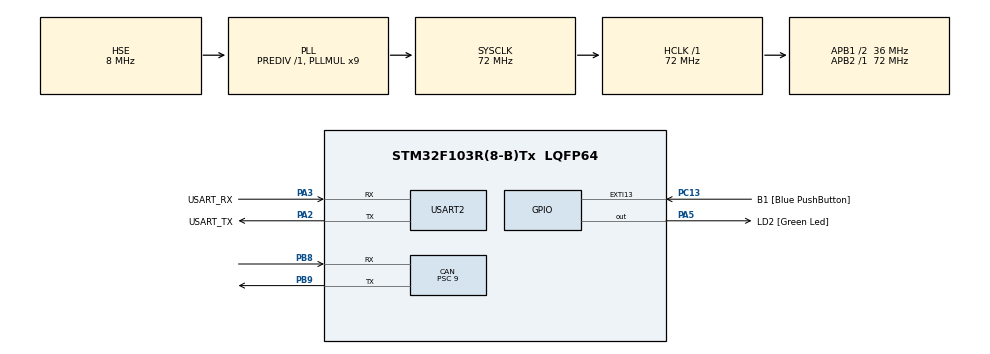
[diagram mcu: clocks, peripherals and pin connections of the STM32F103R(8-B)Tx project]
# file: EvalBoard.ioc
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CAN.BS1=CAN_BS1_13TQ
CAN.BS2=CAN_BS2_2TQ
CAN.CalculateTimeBit=4000
CAN.CalculateTimeQuantum=250.0
CAN.Prescaler=9
CAN.SJW=CAN_SJW_1TQ
FREERTOS.Tasks01=defaultTask,0,128,StartDefaultTask,Default,NULL
Mcu.Family=STM32F1
Mcu.Name=STM32F103R(8-B)Tx
Mcu.Package=LQFP64
NVIC.CAN1_RX1_IRQn=true\:5\:0\:false\:false\:true\:true\:true
NVIC.CAN1_SCE_IRQn=true\:5\:0\:false\:false\:true\:true\:true
NVIC.EXTI15_10_IRQn=true\:5\:0\:false\:false\:true\:true\:true
NVIC.PriorityGroup=NVIC_PRIORITYGROUP_4
NVIC.USB_HP_CAN1_TX_IRQn=true\:5\:0\:false\:false\:true\:true\:true
NVIC.USB_LP_CAN1_RX0_IRQn=true\:5\:0\:false\:false\:true\:true\:true
PA13.GPIO_Label=TMS
PA13.Mode=Serial_Wire
PA13.Signal=SYS_JTMS-SWDIO
PA14.GPIO_Label=TCK
PA14.Mode=Serial_Wire
PA14.Signal=SYS_JTCK-SWCLK
PA2.GPIO_Label=USART_TX
PA2.GPIO_Mode=GPIO_MODE_AF_PP
PA2.GPIO_PuPd=GPIO_NOPULL
PA2.GPIO_Speed=GPIO_SPEED_FREQ_LOW
PA2.Mode=Asynchronous
PA2.Signal=USART2_TX
PA3.GPIO_Label=USART_RX
PA3.GPIO_Mode=GPIO_MODE_AF_PP
PA3.GPIO_PuPd=GPIO_NOPULL
PA3.GPIO_Speed=GPIO_SPEED_FREQ_LOW
PA3.Mode=Asynchronous
PA3.Signal=USART2_RX
PA5.GPIO_Label=LD2 [Green Led]
PA5.GPIO_ModeDefaultOutputPP=GPIO_MODE_OUTPUT_PP
PA5.GPIO_PuPd=GPIO_NOPULL
PA5.GPIO_Speed=GPIO_SPEED_FREQ_LOW
PA5.Signal=GPIO_Output
PB3.GPIO_Label=SWO
PB3.Signal=SYS_JTDO-TRACESWO
PB8.Mode=Master
PB8.Signal=CAN_RX
PB9.Mode=Master
PB9.Signal=CAN_TX
PC13-TAMPER-RTC.GPIO_Label=B1 [Blue PushButton]
PC13-TAMPER-RTC.GPIO_ModeDefaultEXTI=GPIO_MODE_IT_FALLING
PC13-TAMPER-RTC.GPIO_PuPd=GPIO_NOPULL
PC13-TAMPER-RTC.Signal=GPXTI13
PC14-OSC32_IN.Mode=LSE-External-Oscillator
PC14-OSC32_IN.Signal=RCC_OSC32_IN
PC15-OSC32_OUT.Mode=LSE-External-Oscillator
PC15-OSC32_OUT.Signal=RCC_OSC32_OUT
PD0-OSC_IN.Mode=HSE-External-Oscillator
PD0-OSC_IN.Signal=RCC_OSC_IN
PD1-OSC_OUT.Mode=HSE-External-Oscillator
PD1-OSC_OUT.Signal=RCC_OSC_OUT
ProjectManager.HeapSize=0x200
ProjectManager.StackSize=0x400
ProjectManager.TargetToolchain=TrueSTUDIO
RCC.AHBFreq_Value=72000000
RCC.APB1CLKDivider=RCC_HCLK_DIV2
RCC.APB1Freq_Value=36000000
RCC.APB1TimFreq_Value=72000000
RCC.APB2Freq_Value=72000000
RCC.APB2TimFreq_Value=72000000
RCC.HCLKFreq_Value=72000000
RCC.PLLMUL=RCC_PLL_MUL9
RCC.PLLSourceVirtual=RCC_PLLSOURCE_HSE
RCC.SYSCLKFreq_VALUE=72000000
RCC.SYSCLKSource=RCC_SYSCLKSOURCE_PLLCLK
RCC.USBFreq_Value=72000000
USART2.VirtualMode=VM_ASYNC
VP_FREERTOS_VS_ENABLE.Mode=Enabled
board=NUCLEO-F103RB

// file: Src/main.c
/**
  ******************************************************************************
  * File Name          : main.c
  * Description        : Main program body
  ******************************************************************************
  * This notice applies to any and all portions of this file
  * that are not between comment pairs USER CODE BEGIN and
  * USER CODE END. Other portions of this file, whether
  * inserted by the user or by software development tools
  * are owned by their respective copyright owners.
  *
  * Copyright (c) 2017 STMicroelectronics International N.V.
  * All rights reserved.
  *
  * Redistribution and use in source and binary forms, with or without
  * modification, are permitted, provided that the following conditions are met:
  *
  * 1. Redistribution of source code must retain the above copyright notice,
  *    this list of conditions and the following disclaimer.
  * 2. Redistributions in binary form must reproduce the above copyright notice,
  *    this list of conditions and the following disclaimer in the documentation
  *    and/or other materials provided with the distribution.
  * 3. Neither the name of STMicroelectronics nor the names of other
  *    contributors to this software may be used to endorse or promote products
  *    derived from this software without specific written permission.
  * 4. This software, including modifications and/or derivative works of this
  *    software, must execute solely and exclusively on microcontroller or
  *    microprocessor devices manufactured by or for STMicroelectronics.
  * 5. Redistribution and use of this software other than as permitted under
  *    this license is void and will automatically terminate your rights under
  *    this license.
  *
  * THIS SOFTWARE IS PROVIDED BY STMICROELECTRONICS AND CONTRIBUTORS "AS IS"
  * AND ANY EXPRESS, IMPLIED OR STATUTORY WARRANTIES, INCLUDING, BUT NOT
  * LIMITED TO, THE IMPLIED WARRANTIES OF MERCHANTABILITY, FITNESS FOR A
  * PARTICULAR PURPOSE AND NON-INFRINGEMENT OF THIRD PARTY INTELLECTUAL PROPERTY
  * RIGHTS ARE DISCLAIMED TO THE FULLEST EXTENT PERMITTED BY LAW. IN NO EVENT
  * SHALL STMICROELECTRONICS OR CONTRIBUTORS BE LIABLE FOR ANY DIRECT, INDIRECT,
  * INCIDENTAL, SPECIAL, EXEMPLARY, OR CONSEQUENTIAL DAMAGES (INCLUDING, BUT NOT
  * LIMITED TO, PROCUREMENT OF SUBSTITUTE GOODS OR SERVICES; LOSS OF USE, DATA,
  * OR PROFITS; OR BUSINESS INTERRUPTION) HOWEVER CAUSED AND ON ANY THEORY OF
  * LIABILITY, WHETHER IN CONTRACT, STRICT LIABILITY, OR TORT (INCLUDING
  * NEGLIGENCE OR OTHERWISE) ARISING IN ANY WAY OUT OF THE USE OF THIS SOFTWARE,
  * EVEN IF ADVISED OF THE POSSIBILITY OF SUCH DAMAGE.
  *
  ******************************************************************************
  */

#include "main.h"
#include "stm32f1xx_hal.h"
#include "cmsis_os.h"
#include "can.h"
#include "usart.h"
#include "gpio.h"

/* USER CODE BEGIN Includes */
#include "tasks/tasks.h"
/* USER CODE END Includes */

/* USER CODE BEGIN PV */
/* Private variables ---------------------------------------------------------*/

/* USER CODE END PV */

void SystemClock_Config(void);
void MX_FREERTOS_Init(void);

/* USER CODE BEGIN PFP */
/* Private function prototypes -----------------------------------------------*/

/* USER CODE END PFP */

int main(void)
{

  /* MCU Configuration----------------------------------------------------------*/

  /* Reset of all peripherals, Initializes the Flash interface and the Systick. */
  HAL_Init();

  /* Configure the system clock */
  SystemClock_Config();

  /* Initialize all configured peripherals */
  MX_GPIO_Init();
  MX_CAN_Init();
  MX_USART2_UART_Init();

  /* USER CODE BEGIN 2 */
  if (xTaskCreate(heartbeat_task, "TP", configMINIMAL_STACK_SIZE, NULL, configMAX_PRIORITIES-1, NULL) != pdPASS){
  // PRINTF("Failed to create slave task");
  }
  if (xTaskCreate(can_task, "can", configMINIMAL_STACK_SIZE, NULL, configMAX_PRIORITIES-1, NULL) != pdPASS){
  // PRINTF("Failed to create slave task");
  }

  /* USER CODE END 2 */

  /* Call init function for freertos objects (in freertos.c) */
  MX_FREERTOS_Init();

  /* Start scheduler */
  osKernelStart();

  /* We should never get here as control is now taken by the scheduler */

  /* Infinite loop */
  while (1)
  {

  }

}

/** System Clock Configuration
*/
void SystemClock_Config(void)
{

  RCC_OscInitTypeDef RCC_OscInitStruct;
  RCC_ClkInitTypeDef RCC_ClkInitStruct;

    /**Initializes the CPU, AHB and APB busses clocks
    */
  RCC_OscInitStruct.OscillatorType = RCC_OSCILLATORTYPE_HSE;
  RCC_OscInitStruct.HSEState = RCC_HSE_ON;
  RCC_OscInitStruct.HSEPredivValue = RCC_HSE_PREDIV_DIV1;
  RCC_OscInitStruct.HSIState = RCC_HSI_ON;
  RCC_OscInitStruct.PLL.PLLState = RCC_PLL_ON;
  RCC_OscInitStruct.PLL.PLLSource = RCC_PLLSOURCE_HSE;
  RCC_OscInitStruct.PLL.PLLMUL = RCC_PLL_MUL9;
  if (HAL_RCC_OscConfig(&RCC_OscInitStruct) != HAL_OK)
  {
    _Error_Handler(__FILE__, __LINE__);
  }

    /**Initializes the CPU, AHB and APB busses clocks
    */
  RCC_ClkInitStruct.ClockType = RCC_CLOCKTYPE_HCLK|RCC_CLOCKTYPE_SYSCLK
                              |RCC_CLOCKTYPE_PCLK1|RCC_CLOCKTYPE_PCLK2;
  RCC_ClkInitStruct.SYSCLKSource = RCC_SYSCLKSOURCE_PLLCLK;
  RCC_ClkInitStruct.AHBCLKDivider = RCC_SYSCLK_DIV1;
  RCC_ClkInitStruct.APB1CLKDivider = RCC_HCLK_DIV2;
  RCC_ClkInitStruct.APB2CLKDivider = RCC_HCLK_DIV1;

  if (HAL_RCC_ClockConfig(&RCC_ClkInitStruct, FLASH_LATENCY_2) != HAL_OK)
  {
    _Error_Handler(__FILE__, __LINE__);
  }

    /**Configure the Systick interrupt time
    */
  HAL_SYSTICK_Config(HAL_RCC_GetHCLKFreq()/1000);

    /**Configure the Systick
    */
  HAL_SYSTICK_CLKSourceConfig(SYSTICK_CLKSOURCE_HCLK);

  /* SysTick_IRQn interrupt configuration */
  HAL_NVIC_SetPriority(SysTick_IRQn, 15, 0);
}

void _Error_Handler(char * file, int line)
{
  while(1)
  {
  }
}

/************************ (C) COPYRIGHT STMicroelectronics *****END OF FILE****/
